# RX64M_CRC_Pilot register map
File version: 1.0
RX64M_CRC_Pilot peripheral registers generated from iodefine.h (pilot).
Registers are 8-bit, read-write, reset 0x0 unless marked. A register's access mark holds for its fields unless they carry their own. Offsets are from the block's base; lines under a group give offsets from that group; [hi:lo] are bit positions; {n}, {i} and the like mark numbered series; 'fields as' and 'values as' point back to an identical list; <NAME> marks a mode.

## Memory map
0x00088280 CRC size 0x4

## CRC
Base 0x00088280
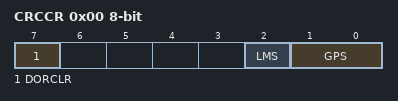
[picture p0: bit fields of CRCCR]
0x00 CRCCR
  [7] DORCLR, [2] LMS, [1:0] GPS
0x01 CRCDIR
0x02 CRCDOR 16-bit
